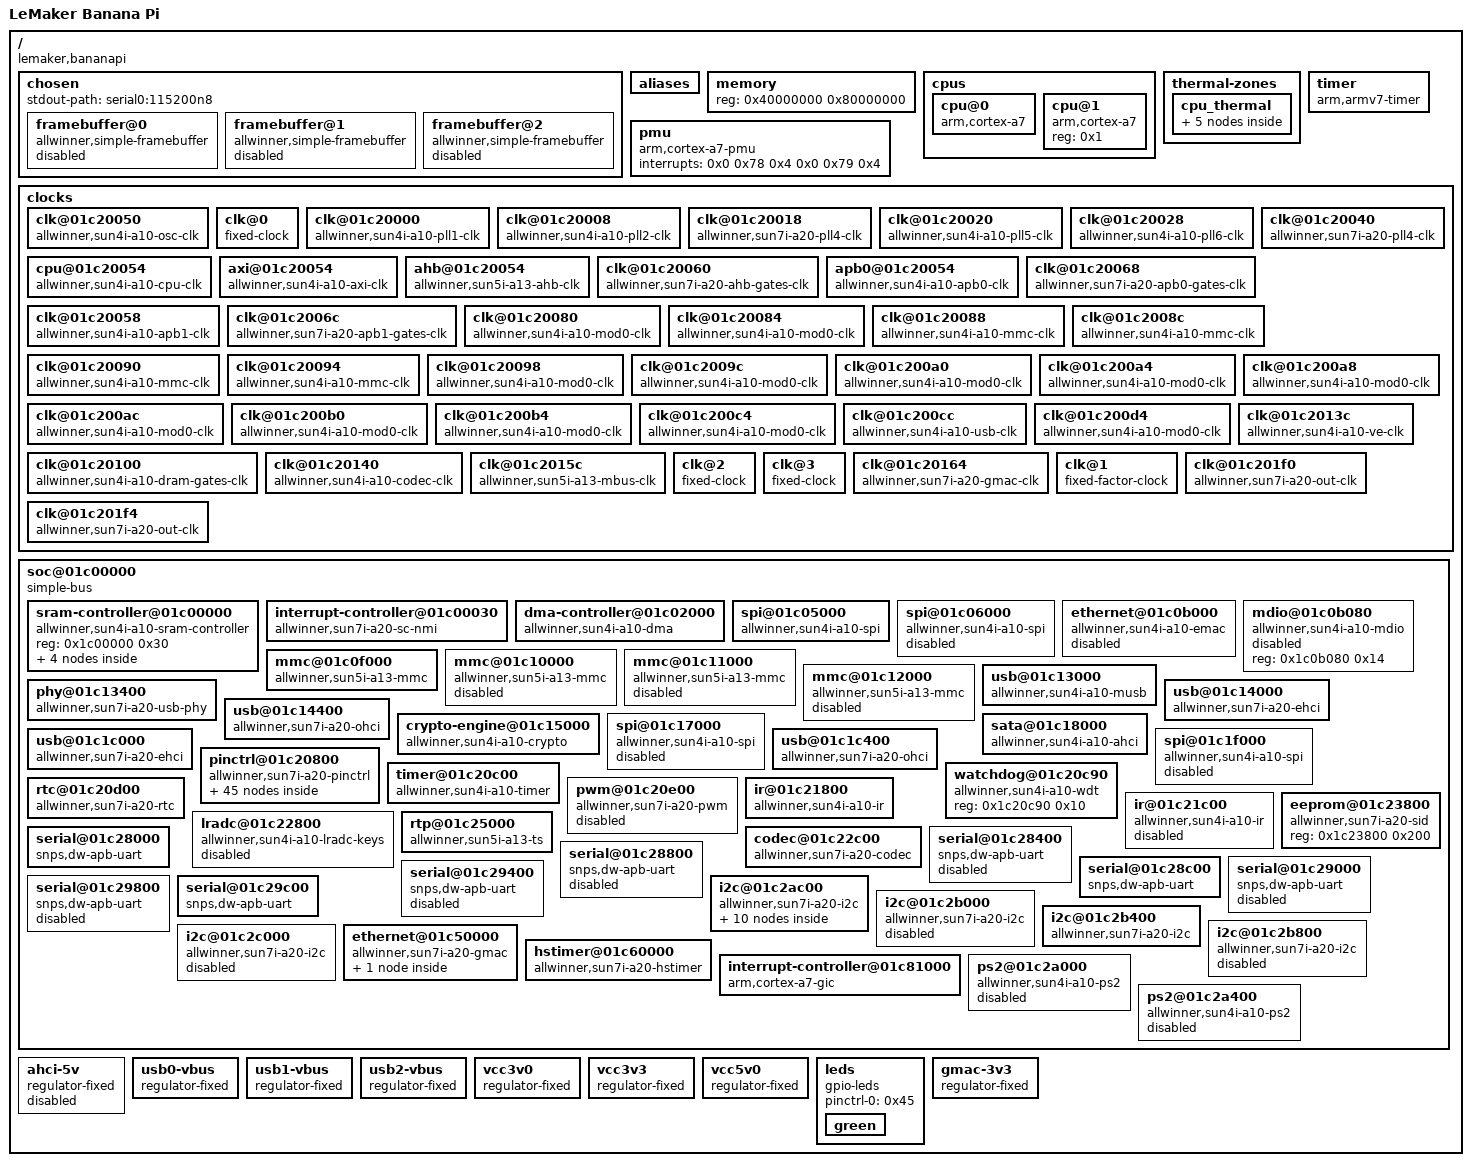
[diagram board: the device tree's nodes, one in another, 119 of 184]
/dts-v1/;

/ {
	#address-cells = <0x1>;
	#size-cells = <0x1>;
	interrupt-parent = <0x1>;
	model = "LeMaker Banana Pi";
	compatible = "lemaker,bananapi", "allwinner,sun7i-a20";

	chosen {
		#address-cells = <0x1>;
		#size-cells = <0x1>;
		ranges;
		stdout-path = "serial0:115200n8";

		framebuffer@0 {
			compatible = "allwinner,simple-framebuffer", "simple-framebuffer";
			allwinner,pipeline = "de_be0-lcd0-hdmi";
			clocks = <0x2 0x1 0x3 0x24 0x3 0x2b 0x3 0x2c 0x4 0x1a>;
			status = "disabled";
		};

		framebuffer@1 {
			compatible = "allwinner,simple-framebuffer", "simple-framebuffer";
			allwinner,pipeline = "de_be0-lcd0";
			clocks = <0x2 0x1 0x3 0x24 0x3 0x2c 0x4 0x1a>;
			status = "disabled";
		};

		framebuffer@2 {
			compatible = "allwinner,simple-framebuffer", "simple-framebuffer";
			allwinner,pipeline = "de_be0-lcd0-tve0";
			clocks = <0x2 0x1 0x3 0x22 0x3 0x24 0x3 0x2c 0x4 0x1a>;
			status = "disabled";
		};
	};

	aliases {
		ethernet0 = "/soc@01c00000/ethernet@01c50000";
		serial0 = "/soc@01c00000/serial@01c28000";
		serial1 = "/soc@01c00000/serial@01c28c00";
		serial2 = "/soc@01c00000/serial@01c29c00";
	};

	memory {
		device_type = "memory";
		reg = <0x40000000 0x80000000>;
	};

	cpus {
		#address-cells = <0x1>;
		#size-cells = <0x0>;

		cpu@0 {
			compatible = "arm,cortex-a7";
			device_type = "cpu";
			reg = <0x0>;
			clocks = <0x5>;
			clock-latency = <0x3b9b0>;
			operating-points = <0xea600 0x155cc0 0xdea80 0x155cc0 0xd2f00 0x149970 0xafc80 0x1312d0 0x80e80 0x118c30 0x4c2c0 0x10c8e0 0x23280 0x100590>;
			#cooling-cells = <0x2>;
			cooling-min-level = <0x0>;
			cooling-max-level = <0x6>;
			cpu-supply = <0x6>;
			linux,phandle = <0x9>;
			phandle = <0x9>;
		};

		cpu@1 {
			compatible = "arm,cortex-a7";
			device_type = "cpu";
			reg = <0x1>;
		};
	};

	thermal-zones {

		cpu_thermal {
			polling-delay-passive = <0xfa>;
			polling-delay = <0x3e8>;
			thermal-sensors = <0x7>;

			cooling-maps {

				map0 {
					trip = <0x8>;
					cooling-device = <0x9 0xffffffff 0xffffffff>;
				};
			};

			trips {

				cpu_alert0 {
					temperature = <0x124f8>;
					hysteresis = <0x7d0>;
					type = "passive";
					linux,phandle = <0x8>;
					phandle = <0x8>;
				};

				cpu_crit {
					temperature = <0x186a0>;
					hysteresis = <0x7d0>;
					type = "critical";
				};
			};
		};
	};

	timer {
		compatible = "arm,armv7-timer";
		interrupts = <0x1 0xd 0xf08 0x1 0xe 0xf08 0x1 0xb 0xf08 0x1 0xa 0xf08>;
	};

	pmu {
		compatible = "arm,cortex-a7-pmu", "arm,cortex-a15-pmu";
		interrupts = <0x0 0x78 0x4 0x0 0x79 0x4>;
	};

	clocks {
		#address-cells = <0x1>;
		#size-cells = <0x1>;
		ranges;

		clk@01c20050 {
			#clock-cells = <0x0>;
			compatible = "allwinner,sun4i-a10-osc-clk";
			reg = <0x1c20050 0x4>;
			clock-frequency = <0x16e3600>;
			clock-output-names = "osc24M";
			linux,phandle = <0xa>;
			phandle = <0xa>;
		};

		clk@0 {
			#clock-cells = <0x0>;
			compatible = "fixed-clock";
			clock-frequency = <0x8000>;
			clock-output-names = "osc32k";
			linux,phandle = <0xb>;
			phandle = <0xb>;
		};

		clk@01c20000 {
			#clock-cells = <0x0>;
			compatible = "allwinner,sun4i-a10-pll1-clk";
			reg = <0x1c20000 0x4>;
			clocks = <0xa>;
			clock-output-names = "pll1";
			linux,phandle = <0xc>;
			phandle = <0xc>;
		};

		clk@01c20008 {
			#clock-cells = <0x1>;
			compatible = "allwinner,sun4i-a10-pll2-clk";
			reg = <0x1c20008 0x8>;
			clocks = <0xa>;
			clock-output-names = "pll2-1x", "pll2-2x", "pll2-4x", "pll2-8x";
			linux,phandle = <0x13>;
			phandle = <0x13>;
		};

		clk@01c20018 {
			#clock-cells = <0x0>;
			compatible = "allwinner,sun7i-a20-pll4-clk";
			reg = <0x1c20018 0x4>;
			clocks = <0xa>;
			clock-output-names = "pll4";
			linux,phandle = <0x12>;
			phandle = <0x12>;
		};

		clk@01c20020 {
			#clock-cells = <0x1>;
			compatible = "allwinner,sun4i-a10-pll5-clk";
			reg = <0x1c20020 0x4>;
			clocks = <0xa>;
			clock-output-names = "pll5_ddr", "pll5_other";
			linux,phandle = <0x2>;
			phandle = <0x2>;
		};

		clk@01c20028 {
			#clock-cells = <0x1>;
			compatible = "allwinner,sun4i-a10-pll6-clk";
			reg = <0x1c20028 0x4>;
			clocks = <0xa>;
			clock-output-names = "pll6_sata", "pll6_other", "pll6", "pll6_div_4";
			linux,phandle = <0xd>;
			phandle = <0xd>;
		};

		clk@01c20040 {
			#clock-cells = <0x0>;
			compatible = "allwinner,sun7i-a20-pll4-clk";
			reg = <0x1c20040 0x4>;
			clocks = <0xa>;
			clock-output-names = "pll8";
		};

		cpu@01c20054 {
			#clock-cells = <0x0>;
			compatible = "allwinner,sun4i-a10-cpu-clk";
			reg = <0x1c20054 0x4>;
			clocks = <0xb 0xa 0xc 0xd 0x1>;
			clock-output-names = "cpu";
			linux,phandle = <0x5>;
			phandle = <0x5>;
		};

		axi@01c20054 {
			#clock-cells = <0x0>;
			compatible = "allwinner,sun4i-a10-axi-clk";
			reg = <0x1c20054 0x4>;
			clocks = <0x5>;
			clock-output-names = "axi";
			linux,phandle = <0xe>;
			phandle = <0xe>;
		};

		ahb@01c20054 {
			#clock-cells = <0x0>;
			compatible = "allwinner,sun5i-a13-ahb-clk";
			reg = <0x1c20054 0x4>;
			clocks = <0xe 0xd 0x3 0xd 0x1>;
			clock-output-names = "ahb";
			assigned-clocks = <0xf>;
			assigned-clock-parents = <0xd 0x3>;
			linux,phandle = <0xf>;
			phandle = <0xf>;
		};

		clk@01c20060 {
			#clock-cells = <0x1>;
			compatible = "allwinner,sun7i-a20-ahb-gates-clk";
			reg = <0x1c20060 0x8>;
			clocks = <0xf>;
			clock-indices = <0x0 0x1 0x2 0x3 0x4 0x5 0x6 0x7 0x8 0x9 0xa 0xb 0xc 0xd 0xe 0x10 0x11 0x12 0x14 0x15 0x16 0x17 0x19 0x1c 0x20 0x21 0x22 0x23 0x24 0x25 0x28 0x29 0x2a 0x2b 0x2c 0x2d 0x2e 0x2f 0x31 0x32 0x34>;
			clock-output-names = "ahb_usb0", "ahb_ehci0", "ahb_ohci0", "ahb_ehci1", "ahb_ohci1", "ahb_ss", "ahb_dma", "ahb_bist", "ahb_mmc0", "ahb_mmc1", "ahb_mmc2", "ahb_mmc3", "ahb_ms", "ahb_nand", "ahb_sdram", "ahb_ace", "ahb_emac", "ahb_ts", "ahb_spi0", "ahb_spi1", "ahb_spi2", "ahb_spi3", "ahb_sata", "ahb_hstimer", "ahb_ve", "ahb_tvd", "ahb_tve0", "ahb_tve1", "ahb_lcd0", "ahb_lcd1", "ahb_csi0", "ahb_csi1", "ahb_hdmi1", "ahb_hdmi0", "ahb_de_be0", "ahb_de_be1", "ahb_de_fe0", "ahb_de_fe1", "ahb_gmac", "ahb_mp", "ahb_mali";
			linux,phandle = <0x3>;
			phandle = <0x3>;
		};

		apb0@01c20054 {
			#clock-cells = <0x0>;
			compatible = "allwinner,sun4i-a10-apb0-clk";
			reg = <0x1c20054 0x4>;
			clocks = <0xf>;
			clock-output-names = "apb0";
			linux,phandle = <0x10>;
			phandle = <0x10>;
		};

		clk@01c20068 {
			#clock-cells = <0x1>;
			compatible = "allwinner,sun7i-a20-apb0-gates-clk";
			reg = <0x1c20068 0x4>;
			clocks = <0x10>;
			clock-indices = <0x0 0x1 0x2 0x3 0x4 0x5 0x6 0x7 0x8 0xa>;
			clock-output-names = "apb0_codec", "apb0_spdif", "apb0_ac97", "apb0_iis0", "apb0_iis1", "apb0_pio", "apb0_ir0", "apb0_ir1", "apb0_iis2", "apb0_keypad";
			linux,phandle = <0x31>;
			phandle = <0x31>;
		};

		clk@01c20058 {
			#clock-cells = <0x0>;
			compatible = "allwinner,sun4i-a10-apb1-clk";
			reg = <0x1c20058 0x4>;
			clocks = <0xa 0xd 0x1 0xb>;
			clock-output-names = "apb1";
			linux,phandle = <0x11>;
			phandle = <0x11>;
		};

		clk@01c2006c {
			#clock-cells = <0x1>;
			compatible = "allwinner,sun7i-a20-apb1-gates-clk";
			reg = <0x1c2006c 0x4>;
			clocks = <0x11>;
			clock-indices = <0x0 0x1 0x2 0x3 0x4 0x5 0x6 0x7 0xf 0x10 0x11 0x12 0x13 0x14 0x15 0x16 0x17>;
			clock-output-names = "apb1_i2c0", "apb1_i2c1", "apb1_i2c2", "apb1_i2c3", "apb1_can", "apb1_scr", "apb1_ps20", "apb1_ps21", "apb1_i2c4", "apb1_uart0", "apb1_uart1", "apb1_uart2", "apb1_uart3", "apb1_uart4", "apb1_uart5", "apb1_uart6", "apb1_uart7";
			linux,phandle = <0x36>;
			phandle = <0x36>;
		};

		clk@01c20080 {
			#clock-cells = <0x0>;
			compatible = "allwinner,sun4i-a10-mod0-clk";
			reg = <0x1c20080 0x4>;
			clocks = <0xa 0xd 0x1 0x2 0x1>;
			clock-output-names = "nand";
		};

		clk@01c20084 {
			#clock-cells = <0x0>;
			compatible = "allwinner,sun4i-a10-mod0-clk";
			reg = <0x1c20084 0x4>;
			clocks = <0xa 0xd 0x1 0x2 0x1>;
			clock-output-names = "ms";
		};

		clk@01c20088 {
			#clock-cells = <0x1>;
			compatible = "allwinner,sun4i-a10-mmc-clk";
			reg = <0x1c20088 0x4>;
			clocks = <0xa 0xd 0x1 0x2 0x1>;
			clock-output-names = "mmc0", "mmc0_output", "mmc0_sample";
			linux,phandle = <0x1e>;
			phandle = <0x1e>;
		};

		clk@01c2008c {
			#clock-cells = <0x1>;
			compatible = "allwinner,sun4i-a10-mmc-clk";
			reg = <0x1c2008c 0x4>;
			clocks = <0xa 0xd 0x1 0x2 0x1>;
			clock-output-names = "mmc1", "mmc1_output", "mmc1_sample";
			linux,phandle = <0x23>;
			phandle = <0x23>;
		};

		clk@01c20090 {
			#clock-cells = <0x1>;
			compatible = "allwinner,sun4i-a10-mmc-clk";
			reg = <0x1c20090 0x4>;
			clocks = <0xa 0xd 0x1 0x2 0x1>;
			clock-output-names = "mmc2", "mmc2_output", "mmc2_sample";
			linux,phandle = <0x24>;
			phandle = <0x24>;
		};

		clk@01c20094 {
			#clock-cells = <0x1>;
			compatible = "allwinner,sun4i-a10-mmc-clk";
			reg = <0x1c20094 0x4>;
			clocks = <0xa 0xd 0x1 0x2 0x1>;
			clock-output-names = "mmc3", "mmc3_output", "mmc3_sample";
			linux,phandle = <0x25>;
			phandle = <0x25>;
		};

		clk@01c20098 {
			#clock-cells = <0x0>;
			compatible = "allwinner,sun4i-a10-mod0-clk";
			reg = <0x1c20098 0x4>;
			clocks = <0xa 0xd 0x1 0x2 0x1>;
			clock-output-names = "ts";
		};

		clk@01c2009c {
			#clock-cells = <0x0>;
			compatible = "allwinner,sun4i-a10-mod0-clk";
			reg = <0x1c2009c 0x4>;
			clocks = <0xa 0xd 0x1 0x2 0x1>;
			clock-output-names = "ss";
			linux,phandle = <0x2e>;
			phandle = <0x2e>;
		};

		clk@01c200a0 {
			#clock-cells = <0x0>;
			compatible = "allwinner,sun4i-a10-mod0-clk";
			reg = <0x1c200a0 0x4>;
			clocks = <0xa 0xd 0x1 0x2 0x1>;
			clock-output-names = "spi0";
			linux,phandle = <0x17>;
			phandle = <0x17>;
		};

		clk@01c200a4 {
			#clock-cells = <0x0>;
			compatible = "allwinner,sun4i-a10-mod0-clk";
			reg = <0x1c200a4 0x4>;
			clocks = <0xa 0xd 0x1 0x2 0x1>;
			clock-output-names = "spi1";
			linux,phandle = <0x1c>;
			phandle = <0x1c>;
		};

		clk@01c200a8 {
			#clock-cells = <0x0>;
			compatible = "allwinner,sun4i-a10-mod0-clk";
			reg = <0x1c200a8 0x4>;
			clocks = <0xa 0xd 0x1 0x2 0x1>;
			clock-output-names = "spi2";
			linux,phandle = <0x2f>;
			phandle = <0x2f>;
		};

		clk@01c200ac {
			#clock-cells = <0x0>;
			compatible = "allwinner,sun4i-a10-mod0-clk";
			reg = <0x1c200ac 0x4>;
			clocks = <0xa 0xd 0x1 0x2 0x1>;
			clock-output-names = "pata";
		};

		clk@01c200b0 {
			#clock-cells = <0x0>;
			compatible = "allwinner,sun4i-a10-mod0-clk";
			reg = <0x1c200b0 0x4>;
			clocks = <0xa 0xd 0x1 0x2 0x1>;
			clock-output-names = "ir0";
			linux,phandle = <0x32>;
			phandle = <0x32>;
		};

		clk@01c200b4 {
			#clock-cells = <0x0>;
			compatible = "allwinner,sun4i-a10-mod0-clk";
			reg = <0x1c200b4 0x4>;
			clocks = <0xa 0xd 0x1 0x2 0x1>;
			clock-output-names = "ir1";
			linux,phandle = <0x34>;
			phandle = <0x34>;
		};

		clk@01c200c4 {
			#clock-cells = <0x0>;
			compatible = "allwinner,sun4i-a10-mod0-clk";
			reg = <0x1c200c4 0x4>;
			clocks = <0xa>;
			clock-output-names = "keypad";
		};

		clk@01c200cc {
			#clock-cells = <0x1>;
			#reset-cells = <0x1>;
			compatible = "allwinner,sun4i-a10-usb-clk";
			reg = <0x1c200cc 0x4>;
			clocks = <0xd 0x1>;
			clock-output-names = "usb_ohci0", "usb_ohci1", "usb_phy";
			linux,phandle = <0x28>;
			phandle = <0x28>;
		};

		clk@01c200d4 {
			#clock-cells = <0x0>;
			compatible = "allwinner,sun4i-a10-mod0-clk";
			reg = <0x1c200d4 0x4>;
			clocks = <0xa 0xd 0x1 0x2 0x1>;
			clock-output-names = "spi3";
			linux,phandle = <0x30>;
			phandle = <0x30>;
		};

		clk@01c20100 {
			#clock-cells = <0x1>;
			compatible = "allwinner,sun4i-a10-dram-gates-clk";
			reg = <0x1c20100 0x4>;
			clocks = <0x2 0x0>;
			clock-indices = <0x0 0x1 0x2 0x3 0x4 0x5 0x6 0xf 0x18 0x19 0x1a 0x1b 0x1c 0x1d>;
			clock-output-names = "dram_ve", "dram_csi0", "dram_csi1", "dram_ts", "dram_tvd", "dram_tve0", "dram_tve1", "dram_output", "dram_de_fe1", "dram_de_fe0", "dram_de_be0", "dram_de_be1", "dram_de_mp", "dram_ace";
			linux,phandle = <0x4>;
			phandle = <0x4>;
		};

		clk@01c2013c {
			#clock-cells = <0x0>;
			#reset-cells = <0x0>;
			compatible = "allwinner,sun4i-a10-ve-clk";
			reg = <0x1c2013c 0x4>;
			clocks = <0x12>;
			clock-output-names = "ve";
		};

		clk@01c20140 {
			#clock-cells = <0x0>;
			compatible = "allwinner,sun4i-a10-codec-clk";
			reg = <0x1c20140 0x4>;
			clocks = <0x13 0x0>;
			clock-output-names = "codec";
			linux,phandle = <0x35>;
			phandle = <0x35>;
		};

		clk@01c2015c {
			#clock-cells = <0x0>;
			compatible = "allwinner,sun5i-a13-mbus-clk";
			reg = <0x1c2015c 0x4>;
			clocks = <0xa 0xd 0x2 0x2 0x1>;
			clock-output-names = "mbus";
		};

		clk@2 {
			#clock-cells = <0x0>;
			compatible = "fixed-clock";
			clock-frequency = <0x17d7840>;
			clock-output-names = "mii_phy_tx";
			linux,phandle = <0x14>;
			phandle = <0x14>;
		};

		clk@3 {
			#clock-cells = <0x0>;
			compatible = "fixed-clock";
			clock-frequency = <0x7735940>;
			clock-output-names = "gmac_int_tx";
			linux,phandle = <0x15>;
			phandle = <0x15>;
		};

		clk@01c20164 {
			#clock-cells = <0x0>;
			compatible = "allwinner,sun7i-a20-gmac-clk";
			reg = <0x1c20164 0x4>;
			clocks = <0x14 0x15>;
			clock-output-names = "gmac_tx";
			linux,phandle = <0x3d>;
			phandle = <0x3d>;
		};

		clk@1 {
			#clock-cells = <0x0>;
			compatible = "fixed-factor-clock";
			clock-div = <0x2ee>;
			clock-mult = <0x1>;
			clocks = <0xa>;
			clock-output-names = "osc24M_32k";
			linux,phandle = <0x16>;
			phandle = <0x16>;
		};

		clk@01c201f0 {
			#clock-cells = <0x0>;
			compatible = "allwinner,sun7i-a20-out-clk";
			reg = <0x1c201f0 0x4>;
			clocks = <0x16 0xb 0xa>;
			clock-output-names = "clk_out_a";
		};

		clk@01c201f4 {
			#clock-cells = <0x0>;
			compatible = "allwinner,sun7i-a20-out-clk";
			reg = <0x1c201f4 0x4>;
			clocks = <0x16 0xb 0xa>;
			clock-output-names = "clk_out_b";
		};
	};

	soc@01c00000 {
		compatible = "simple-bus";
		#address-cells = <0x1>;
		#size-cells = <0x1>;
		ranges;

		sram-controller@01c00000 {
			compatible = "allwinner,sun4i-a10-sram-controller";
			reg = <0x1c00000 0x30>;
			#address-cells = <0x1>;
			#size-cells = <0x1>;
			ranges;

			sram@00000000 {
				compatible = "mmio-sram";
				reg = <0x0 0xc000>;
				#address-cells = <0x1>;
				#size-cells = <0x1>;
				ranges = <0x0 0x0 0xc000>;

				sram-section@8000 {
					compatible = "allwinner,sun4i-a10-sram-a3-a4";
					reg = <0x8000 0x4000>;
					status = "disabled";
					linux,phandle = <0x1d>;
					phandle = <0x1d>;
				};
			};

			sram@00010000 {
				compatible = "mmio-sram";
				reg = <0x10000 0x1000>;
				#address-cells = <0x1>;
				#size-cells = <0x1>;
				ranges = <0x0 0x10000 0x1000>;

				sram-section@0000 {
					compatible = "allwinner,sun4i-a10-sram-d";
					reg = <0x0 0x1000>;
					status = "okay";
					linux,phandle = <0x27>;
					phandle = <0x27>;
				};
			};
		};

		interrupt-controller@01c00030 {
			compatible = "allwinner,sun7i-a20-sc-nmi";
			interrupt-controller;
			#interrupt-cells = <0x2>;
			reg = <0x1c00030 0xc>;
			interrupts = <0x0 0x0 0x4>;
			linux,phandle = <0x3b>;
			phandle = <0x3b>;
		};

		dma-controller@01c02000 {
			compatible = "allwinner,sun4i-a10-dma";
			reg = <0x1c02000 0x1000>;
			interrupts = <0x0 0x1b 0x4>;
			clocks = <0x3 0x6>;
			#dma-cells = <0x2>;
			linux,phandle = <0x18>;
			phandle = <0x18>;
		};

		spi@01c05000 {
			compatible = "allwinner,sun4i-a10-spi";
			reg = <0x1c05000 0x1000>;
			interrupts = <0x0 0xa 0x4>;
			clocks = <0x3 0x14 0x17>;
			clock-names = "ahb", "mod";
			dmas = <0x18 0x1 0x1b 0x18 0x1 0x1a>;
			dma-names = "rx", "tx";
			status = "okay";
			#address-cells = <0x1>;
			#size-cells = <0x0>;
			pinctrl-names = "default";
			pinctrl-0 = <0x19 0x1a 0x1b>;
		};

		spi@01c06000 {
			compatible = "allwinner,sun4i-a10-spi";
			reg = <0x1c06000 0x1000>;
			interrupts = <0x0 0xb 0x4>;
			clocks = <0x3 0x15 0x1c>;
			clock-names = "ahb", "mod";
			dmas = <0x18 0x1 0x9 0x18 0x1 0x8>;
			dma-names = "rx", "tx";
			status = "disabled";
			#address-cells = <0x1>;
			#size-cells = <0x0>;
		};

		ethernet@01c0b000 {
			compatible = "allwinner,sun4i-a10-emac";
			reg = <0x1c0b000 0x1000>;
			interrupts = <0x0 0x37 0x4>;
			clocks = <0x3 0x11>;
			allwinner,sram = <0x1d 0x1>;
			status = "disabled";
		};

		mdio@01c0b080 {
			compatible = "allwinner,sun4i-a10-mdio";
			reg = <0x1c0b080 0x14>;
			status = "disabled";
			#address-cells = <0x1>;
			#size-cells = <0x0>;
		};

		mmc@01c0f000 {
			compatible = "allwinner,sun5i-a13-mmc";
			reg = <0x1c0f000 0x1000>;
			clocks = <0x3 0x8 0x1e 0x0 0x1e 0x1 0x1e 0x2>;
			clock-names = "ahb", "mmc", "output", "sample";
			interrupts = <0x0 0x20 0x4>;
			status = "okay";
			#address-cells = <0x1>;
			#size-cells = <0x0>;
			pinctrl-names = "default";
			pinctrl-0 = <0x1f 0x20>;
			vmmc-supply = <0x21>;
			bus-width = <0x4>;
			cd-gpios = <0x22 0x7 0xa 0x0>;
			cd-inverted;
		};

		mmc@01c10000 {
			compatible = "allwinner,sun5i-a13-mmc";
			reg = <0x1c10000 0x1000>;
			clocks = <0x3 0x9 0x23 0x0 0x23 0x1 0x23 0x2>;
			clock-names = "ahb", "mmc", "output", "sample";
			interrupts = <0x0 0x21 0x4>;
			status = "disabled";
			#address-cells = <0x1>;
			#size-cells = <0x0>;
		};

		mmc@01c11000 {
			compatible = "allwinner,sun5i-a13-mmc";
			reg = <0x1c11000 0x1000>;
			clocks = <0x3 0xa 0x24 0x0 0x24 0x1 0x24 0x2>;
			clock-names = "ahb", "mmc", "output", "sample";
			interrupts = <0x0 0x22 0x4>;
			status = "disabled";
			#address-cells = <0x1>;
			#size-cells = <0x0>;
		};

		mmc@01c12000 {
			compatible = "allwinner,sun5i-a13-mmc";
			reg = <0x1c12000 0x1000>;
			clocks = <0x3 0xb 0x25 0x0 0x25 0x1 0x25 0x2>;
			clock-names = "ahb", "mmc", "output", "sample";
			interrupts = <0x0 0x23 0x4>;
			status = "disabled";
			#address-cells = <0x1>;
			#size-cells = <0x0>;
		};

		usb@01c13000 {
			compatible = "allwinner,sun4i-a10-musb";
			reg = <0x1c13000 0x400>;
			clocks = <0x3 0x0>;
			interrupts = <0x0 0x26 0x4>;
			interrupt-names = "mc";
			phys = <0x26 0x0>;
			phy-names = "usb";
			extcon = <0x26 0x0>;
			allwinner,sram = <0x27 0x1>;
			status = "okay";
			dr_mode = "otg";
		};

		phy@01c13400 {
			#phy-cells = <0x1>;
			compatible = "allwinner,sun7i-a20-usb-phy";
			reg = <0x1c13400 0x10 0x1c14800 0x4 0x1c1c800 0x4>;
			reg-names = "phy_ctrl", "pmu1", "pmu2";
			clocks = <0x28 0x8>;
			clock-names = "usb_phy";
			resets = <0x28 0x0 0x28 0x1 0x28 0x2>;
			reset-names = "usb0_reset", "usb1_reset", "usb2_reset";
			status = "okay";
			pinctrl-names = "default";
			pinctrl-0 = <0x29>;
			usb0_vbus-supply = <0x2b>;
			usb1_vbus-supply = <0x2c>;
			usb2_vbus-supply = <0x2d>;
			linux,phandle = <0x26>;
			phandle = <0x26>;
		};

		usb@01c14000 {
			compatible = "allwinner,sun7i-a20-ehci", "generic-ehci";
			reg = <0x1c14000 0x100>;
			interrupts = <0x0 0x27 0x4>;
			clocks = <0x3 0x1>;
			phys = <0x26 0x1>;
			phy-names = "usb";
			status = "okay";
		};

		usb@01c14400 {
			compatible = "allwinner,sun7i-a20-ohci", "generic-ohci";
			reg = <0x1c14400 0x100>;
			interrupts = <0x0 0x40 0x4>;
			clocks = <0x28 0x6 0x3 0x2>;
			phys = <0x26 0x1>;
			phy-names = "usb";
			status = "okay";
		};

		crypto-engine@01c15000 {
			compatible = "allwinner,sun4i-a10-crypto";
			reg = <0x1c15000 0x1000>;
			interrupts = <0x0 0x56 0x4>;
			clocks = <0x3 0x5 0x2e>;
			clock-names = "ahb", "mod";
		};

		spi@01c17000 {
			compatible = "allwinner,sun4i-a10-spi";
			reg = <0x1c17000 0x1000>;
			interrupts = <0x0 0xc 0x4>;
			clocks = <0x3 0x16 0x2f>;
			clock-names = "ahb", "mod";
			dmas = <0x18 0x1 0x1d 0x18 0x1 0x1c>;
			dma-names = "rx", "tx";
			status = "disabled";
			#address-cells = <0x1>;
			#size-cells = <0x0>;
		};

		sata@01c18000 {
			compatible = "allwinner,sun4i-a10-ahci";
			reg = <0x1c18000 0x1000>;
			interrupts = <0x0 0x38 0x4>;
			clocks = <0xd 0x0 0x3 0x19>;
			status = "okay";
		};

		usb@01c1c000 {
			compatible = "allwinner,sun7i-a20-ehci", "generic-ehci";
			reg = <0x1c1c000 0x100>;
			interrupts = <0x0 0x28 0x4>;
			clocks = <0x3 0x3>;
			phys = <0x26 0x2>;
			phy-names = "usb";
			status = "okay";
		};

		usb@01c1c400 {
			compatible = "allwinner,sun7i-a20-ohci", "generic-ohci";
			reg = <0x1c1c400 0x100>;
			interrupts = <0x0 0x41 0x4>;
			clocks = <0x28 0x7 0x3 0x4>;
			phys = <0x26 0x2>;
			phy-names = "usb";
			status = "okay";
		};

		spi@01c1f000 {
			compatible = "allwinner,sun4i-a10-spi";
			reg = <0x1c1f000 0x1000>;
			interrupts = <0x0 0x32 0x4>;
			clocks = <0x3 0x17 0x30>;
			clock-names = "ahb", "mod";
			dmas = <0x18 0x1 0x1f 0x18 0x1 0x1e>;
			dma-names = "rx", "tx";
			status = "disabled";
			#address-cells = <0x1>;
			#size-cells = <0x0>;
		};

		pinctrl@01c20800 {
			compatible = "allwinner,sun7i-a20-pinctrl";
			reg = <0x1c20800 0x400>;
			interrupts = <0x0 0x1c 0x4>;
			clocks = <0x31 0x5>;
			gpio-controller;
			interrupt-controller;
			#interrupt-cells = <0x3>;
			#gpio-cells = <0x3>;
			linux,phandle = <0x22>;
			phandle = <0x22>;

			pwm0@0 {
				allwinner,pins = "PB2";
				allwinner,function = "pwm";
				allwinner,drive = <0x0>;
				allwinner,pull = <0x0>;
			};

			pwm1@0 {
				allwinner,pins = "PI3";
				allwinner,function = "pwm";
				allwinner,drive = <0x0>;
				allwinner,pull = <0x0>;
			};

			uart0@0 {
				allwinner,pins = "PB22", "PB23";
				allwinner,function = "uart0";
				allwinner,drive = <0x0>;
				allwinner,pull = <0x0>;
				linux,phandle = <0x37>;
				phandle = <0x37>;
			};

			uart2@0 {
				allwinner,pins = "PI16", "PI17", "PI18", "PI19";
				allwinner,function = "uart2";
				allwinner,drive = <0x0>;
				allwinner,pull = <0x0>;
			};

			uart3@0 {
				allwinner,pins = "PG6", "PG7", "PG8", "PG9";
				allwinner,function = "uart3";
				allwinner,drive = <0x0>;
				allwinner,pull = <0x0>;
			};

			uart3@1 {
				allwinner,pins = "PH0", "PH1";
				allwinner,function = "uart3";
				allwinner,drive = <0x0>;
				allwinner,pull = <0x0>;
				linux,phandle = <0x38>;
				phandle = <0x38>;
			};

			uart4@0 {
				allwinner,pins = "PG10", "PG11";
				allwinner,function = "uart4";
				allwinner,drive = <0x0>;
				allwinner,pull = <0x0>;
			};

			uart4@1 {
				allwinner,pins = "PH4", "PH5";
				allwinner,function = "uart4";
				allwinner,drive = <0x0>;
				allwinner,pull = <0x0>;
			};

			uart5@0 {
				allwinner,pins = "PI10", "PI11";
				allwinner,function = "uart5";
				allwinner,drive = <0x0>;
				allwinner,pull = <0x0>;
			};

			uart6@0 {
				allwinner,pins = "PI12", "PI13";
				allwinner,function = "uart6";
				allwinner,drive = <0x0>;
				allwinner,pull = <0x0>;
			};

			uart7@0 {
				allwinner,pins = "PI20", "PI21";
				allwinner,function = "uart7";
				allwinner,drive = <0x0>;
				allwinner,pull = <0x0>;
				linux,phandle = <0x39>;
				phandle = <0x39>;
			};

			i2c0@0 {
				allwinner,pins = "PB0", "PB1";
				allwinner,function = "i2c0";
				allwinner,drive = <0x0>;
				allwinner,pull = <0x0>;
				linux,phandle = <0x3a>;
				phandle = <0x3a>;
			};

			i2c1@0 {
				allwinner,pins = "PB18", "PB19";
				allwinner,function = "i2c1";
				allwinner,drive = <0x0>;
				allwinner,pull = <0x0>;
			};

			i2c2@0 {
				allwinner,pins = "PB20", "PB21";
				allwinner,function = "i2c2";
				allwinner,drive = <0x0>;
				allwinner,pull = <0x0>;
				linux,phandle = <0x3c>;
				phandle = <0x3c>;
			};

			i2c3@0 {
				allwinner,pins = "PI0", "PI1";
				allwinner,function = "i2c3";
				allwinner,drive = <0x0>;
				allwinner,pull = <0x0>;
			};

			emac0@0 {
				allwinner,pins = "PA0", "PA1", "PA2", "PA3", "PA4", "PA5", "PA6", "PA7", "PA8", "PA9", "PA10", "PA11", "PA12", "PA13", "PA14", "PA15", "PA16";
				allwinner,function = "emac";
				allwinner,drive = <0x0>;
				allwinner,pull = <0x0>;
			};

			clk_out_a@0 {
				allwinner,pins = "PI12";
				allwinner,function = "clk_out_a";
				allwinner,drive = <0x0>;
				allwinner,pull = <0x0>;
			};

			clk_out_b@0 {
				allwinner,pins = "PI13";
				allwinner,function = "clk_out_b";
				allwinner,drive = <0x0>;
				allwinner,pull = <0x0>;
			};

			gmac_mii@0 {
				allwinner,pins = "PA0", "PA1", "PA2", "PA3", "PA4", "PA5", "PA6", "PA7", "PA8", "PA9", "PA10", "PA11", "PA12", "PA13", "PA14", "PA15", "PA16";
				allwinner,function = "gmac";
				allwinner,drive = <0x0>;
				allwinner,pull = <0x0>;
			};

			gmac_rgmii@0 {
				allwinner,pins = "PA0", "PA1", "PA2", "PA3", "PA4", "PA5", "PA6", "PA7", "PA8", "PA10", "PA11", "PA12", "PA13", "PA15", "PA16";
				allwinner,function = "gmac";
				allwinner,drive = <0x3>;
				allwinner,pull = <0x0>;
				linux,phandle = <0x3e>;
				phandle = <0x3e>;
			};

			spi0@0 {
				allwinner,pins = "PI11", "PI12", "PI13";
				allwinner,function = "spi0";
				allwinner,drive = <0x0>;
				allwinner,pull = <0x0>;
				linux,phandle = <0x19>;
				phandle = <0x19>;
			};

			spi0_cs0@0 {
				allwinner,pins = "PI10";
				allwinner,function = "spi0";
				allwinner,drive = <0x0>;
				allwinner,pull = <0x0>;
				linux,phandle = <0x1a>;
				phandle = <0x1a>;
			};

			spi0_cs1@0 {
				allwinner,pins = "PI14";
				allwinner,function = "spi0";
				allwinner,drive = <0x0>;
				allwinner,pull = <0x0>;
				linux,phandle = <0x1b>;
				phandle = <0x1b>;
			};

			spi1@0 {
				allwinner,pins = "PI17", "PI18", "PI19";
				allwinner,function = "spi1";
				allwinner,drive = <0x0>;
				allwinner,pull = <0x0>;
			};

			spi1_cs0@0 {
				allwinner,pins = "PI16";
				allwinner,function = "spi1";
				allwinner,drive = <0x0>;
				allwinner,pull = <0x0>;
			};

			spi2@0 {
				allwinner,pins = "PC20", "PC21", "PC22";
				allwinner,function = "spi2";
				allwinner,drive = <0x0>;
				allwinner,pull = <0x0>;
			};

			spi2@1 {
				allwinner,pins = "PB15", "PB16", "PB17";
				allwinner,function = "spi2";
				allwinner,drive = <0x0>;
				allwinner,pull = <0x0>;
			};

			spi2_cs0@0 {
				allwinner,pins = "PC19";
				allwinner,function = "spi2";
				allwinner,drive = <0x0>;
				allwinner,pull = <0x0>;
			};

			spi2_cs0@1 {
				allwinner,pins = "PB14";
				allwinner,function = "spi2";
				allwinner,drive = <0x0>;
				allwinner,pull = <0x0>;
			};

			mmc0@0 {
				allwinner,pins = "PF0", "PF1", "PF2", "PF3", "PF4", "PF5";
				allwinner,function = "mmc0";
				allwinner,drive = <0x2>;
				allwinner,pull = <0x0>;
				linux,phandle = <0x1f>;
				phandle = <0x1f>;
			};

			mmc0_cd_pin@0 {
				allwinner,pins = "PH10";
				allwinner,function = "gpio_in";
				allwinner,drive = <0x0>;
				allwinner,pull = <0x1>;
				linux,phandle = <0x20>;
				phandle = <0x20>;
			};

			mmc2@0 {
				allwinner,pins = "PC6", "PC7", "PC8", "PC9", "PC10", "PC11";
				allwinner,function = "mmc2";
				allwinner,drive = <0x2>;
				allwinner,pull = <0x1>;
			};

			mmc3@0 {
				allwinner,pins = "PI4", "PI5", "PI6", "PI7", "PI8", "PI9";
				allwinner,function = "mmc3";
				allwinner,drive = <0x2>;
				allwinner,pull = <0x0>;
			};

			ir0@0 {
				allwinner,pins = "PB4";
				allwinner,function = "ir0";
				allwinner,drive = <0x0>;
				allwinner,pull = <0x0>;
				linux,phandle = <0x33>;
				phandle = <0x33>;
			};

			ir0@1 {
				allwinner,pins = "PB3";
				allwinner,function = "ir0";
				allwinner,drive = <0x0>;
				allwinner,pull = <0x0>;
			};

			ir1@0 {
				allwinner,pins = "PB23";
				allwinner,function = "ir1";
				allwinner,drive = <0x0>;
				allwinner,pull = <0x0>;
			};

			ir1@1 {
				allwinner,pins = "PB22";
				allwinner,function = "ir1";
				allwinner,drive = <0x0>;
				allwinner,pull = <0x0>;
			};

			ps20@0 {
				allwinner,pins = "PI20", "PI21";
				allwinner,function = "ps2";
				allwinner,drive = <0x0>;
				allwinner,pull = <0x0>;
			};

			ps21@0 {
				allwinner,pins = "PH12", "PH13";
				allwinner,function = "ps2";
				allwinner,drive = <0x0>;
				allwinner,pull = <0x0>;
			};

			ahci_pwr_pin@0 {
				allwinner,pins = "PB8";
				allwinner,function = "gpio_out";
				allwinner,drive = <0x0>;
				allwinner,pull = <0x0>;
				linux,phandle = <0x41>;
				phandle = <0x41>;
			};

			usb0_vbus_pin@0 {
				allwinner,pins = "PB9";
				allwinner,function = "gpio_out";
				allwinner,drive = <0x0>;
				allwinner,pull = <0x0>;
				linux,phandle = <0x42>;
				phandle = <0x42>;
			};

			usb1_vbus_pin@0 {
				allwinner,pins = "PH6";
				allwinner,function = "gpio_out";
				allwinner,drive = <0x0>;
				allwinner,pull = <0x0>;
				linux,phandle = <0x43>;
				phandle = <0x43>;
			};

			usb2_vbus_pin@0 {
				allwinner,pins = "PH3";
				allwinner,function = "gpio_out";
				allwinner,drive = <0x0>;
				allwinner,pull = <0x0>;
				linux,phandle = <0x44>;
				phandle = <0x44>;
			};

			gmac_power_pin@0 {
				allwinner,pins = "PH23";
				allwinner,function = "gpio_out";
				allwinner,drive = <0x0>;
				allwinner,pull = <0x0>;
				linux,phandle = <0x46>;
				phandle = <0x46>;
			};

			led_pins@0 {
				allwinner,pins = "PH24";
				allwinner,function = "gpio_out";
				allwinner,drive = <0x0>;
				allwinner,pull = <0x0>;
				linux,phandle = <0x45>;
				phandle = <0x45>;
			};
		};

		timer@01c20c00 {
			compatible = "allwinner,sun4i-a10-timer";
			reg = <0x1c20c00 0x90>;
			interrupts = <0x0 0x16 0x4 0x0 0x17 0x4 0x0 0x18 0x4 0x0 0x19 0x4 0x0 0x43 0x4 0x0 0x44 0x4>;
			clocks = <0xa>;
		};

		watchdog@01c20c90 {
			compatible = "allwinner,sun4i-a10-wdt";
			reg = <0x1c20c90 0x10>;
		};

		rtc@01c20d00 {
			compatible = "allwinner,sun7i-a20-rtc";
			reg = <0x1c20d00 0x20>;
			interrupts = <0x0 0x18 0x4>;
		};

		pwm@01c20e00 {
			compatible = "allwinner,sun7i-a20-pwm";
			reg = <0x1c20e00 0xc>;
			clocks = <0xa>;
			#pwm-cells = <0x3>;
			status = "disabled";
		};

		ir@01c21800 {
			compatible = "allwinner,sun4i-a10-ir";
			clocks = <0x31 0x6 0x32>;
			clock-names = "apb", "ir";
			interrupts = <0x0 0x5 0x4>;
			reg = <0x1c21800 0x40>;
			status = "okay";
			pinctrl-names = "default";
			pinctrl-0 = <0x33>;
		};

		ir@01c21c00 {
			compatible = "allwinner,sun4i-a10-ir";
			clocks = <0x31 0x7 0x34>;
			clock-names = "apb", "ir";
			interrupts = <0x0 0x6 0x4>;
			reg = <0x1c21c00 0x40>;
			status = "disabled";
		};

		lradc@01c22800 {
			compatible = "allwinner,sun4i-a10-lradc-keys";
			reg = <0x1c22800 0x100>;
			interrupts = <0x0 0x1f 0x4>;
			status = "disabled";
		};

		codec@01c22c00 {
			#sound-dai-cells = <0x0>;
			compatible = "allwinner,sun7i-a20-codec";
			reg = <0x1c22c00 0x40>;
			interrupts = <0x0 0x1e 0x4>;
			clocks = <0x31 0x0 0x35>;
			clock-names = "apb", "codec";
			dmas = <0x18 0x0 0x13 0x18 0x0 0x13>;
			dma-names = "rx", "tx";
			status = "okay";
		};

		eeprom@01c23800 {
			compatible = "allwinner,sun7i-a20-sid";
			reg = <0x1c23800 0x200>;
		};

		rtp@01c25000 {
			compatible = "allwinner,sun5i-a13-ts";
			reg = <0x1c25000 0x100>;
			interrupts = <0x0 0x1d 0x4>;
			#thermal-sensor-cells = <0x0>;
			linux,phandle = <0x7>;
			phandle = <0x7>;
		};

		serial@01c28000 {
			compatible = "snps,dw-apb-uart";
			reg = <0x1c28000 0x400>;
			interrupts = <0x0 0x1 0x4>;
			reg-shift = <0x2>;
			reg-io-width = <0x4>;
			clocks = <0x36 0x10>;
			status = "okay";
			pinctrl-names = "default";
			pinctrl-0 = <0x37>;
		};

		serial@01c28400 {
			compatible = "snps,dw-apb-uart";
			reg = <0x1c28400 0x400>;
			interrupts = <0x0 0x2 0x4>;
			reg-shift = <0x2>;
			reg-io-width = <0x4>;
			clocks = <0x36 0x11>;
			status = "disabled";
		};

		serial@01c28800 {
			compatible = "snps,dw-apb-uart";
			reg = <0x1c28800 0x400>;
			interrupts = <0x0 0x3 0x4>;
			reg-shift = <0x2>;
			reg-io-width = <0x4>;
			clocks = <0x36 0x12>;
			status = "disabled";
		};

		serial@01c28c00 {
			compatible = "snps,dw-apb-uart";
			reg = <0x1c28c00 0x400>;
			interrupts = <0x0 0x4 0x4>;
			reg-shift = <0x2>;
			reg-io-width = <0x4>;
			clocks = <0x36 0x13>;
			status = "okay";
			pinctrl-names = "default";
			pinctrl-0 = <0x38>;
		};

		serial@01c29000 {
			compatible = "snps,dw-apb-uart";
			reg = <0x1c29000 0x400>;
			interrupts = <0x0 0x11 0x4>;
			reg-shift = <0x2>;
			reg-io-width = <0x4>;
			clocks = <0x36 0x14>;
			status = "disabled";
		};

		serial@01c29400 {
			compatible = "snps,dw-apb-uart";
			reg = <0x1c29400 0x400>;
			interrupts = <0x0 0x12 0x4>;
			reg-shift = <0x2>;
			reg-io-width = <0x4>;
			clocks = <0x36 0x15>;
			status = "disabled";
		};

		serial@01c29800 {
			compatible = "snps,dw-apb-uart";
			reg = <0x1c29800 0x400>;
			interrupts = <0x0 0x13 0x4>;
			reg-shift = <0x2>;
			reg-io-width = <0x4>;
			clocks = <0x36 0x16>;
			status = "disabled";
		};

		serial@01c29c00 {
			compatible = "snps,dw-apb-uart";
			reg = <0x1c29c00 0x400>;
			interrupts = <0x0 0x14 0x4>;
			reg-shift = <0x2>;
			reg-io-width = <0x4>;
			clocks = <0x36 0x17>;
			status = "okay";
			pinctrl-names = "default";
			pinctrl-0 = <0x39>;
		};

		i2c@01c2ac00 {
			compatible = "allwinner,sun7i-a20-i2c", "allwinner,sun4i-a10-i2c";
			reg = <0x1c2ac00 0x400>;
			interrupts = <0x0 0x7 0x4>;
			clocks = <0x36 0x0>;
			status = "okay";
			#address-cells = <0x1>;
			#size-cells = <0x0>;
			pinctrl-names = "default";
			pinctrl-0 = <0x3a>;

			pmic@34 {
				reg = <0x34>;
				interrupt-parent = <0x3b>;
				interrupts = <0x0 0x8>;
				compatible = "x-powers,axp209";
				interrupt-controller;
				#interrupt-cells = <0x1>;

				regulators {
					x-powers,dcdc-freq = <0x5dc>;

					dcdc2 {
						regulator-name = "vdd-cpu";
						regulator-always-on;
						regulator-min-microvolt = <0xf4240>;
						regulator-max-microvolt = <0x155cc0>;
						linux,phandle = <0x6>;
						phandle = <0x6>;
					};

					dcdc3 {
						regulator-name = "vdd-int-dll";
						regulator-always-on;
						regulator-min-microvolt = <0xf4240>;
						regulator-max-microvolt = <0x155cc0>;
					};

					ldo1 {
						regulator-always-on;
						regulator-min-microvolt = <0x13d620>;
						regulator-max-microvolt = <0x13d620>;
						regulator-name = "vdd-rtc";
					};

					ldo2 {
						regulator-name = "avcc";
						regulator-always-on;
						regulator-min-microvolt = <0x2dc6c0>;
						regulator-max-microvolt = <0x2dc6c0>;
					};

					ldo3 {
						regulator-name = "ldo3";
					};

					ldo4 {
						regulator-name = "ldo4";
					};

					ldo5 {
						regulator-name = "ldo5";
					};
				};

				usb_power_supply {
					compatible = "x-powers,axp202-usb-power-supply";
					status = "okay";
					linux,phandle = <0x2a>;
					phandle = <0x2a>;
				};
			};
		};

		i2c@01c2b000 {
			compatible = "allwinner,sun7i-a20-i2c", "allwinner,sun4i-a10-i2c";
			reg = <0x1c2b000 0x400>;
			interrupts = <0x0 0x8 0x4>;
			clocks = <0x36 0x1>;
			status = "disabled";
			#address-cells = <0x1>;
			#size-cells = <0x0>;
		};

		i2c@01c2b400 {
			compatible = "allwinner,sun7i-a20-i2c", "allwinner,sun4i-a10-i2c";
			reg = <0x1c2b400 0x400>;
			interrupts = <0x0 0x9 0x4>;
			clocks = <0x36 0x2>;
			status = "okay";
			#address-cells = <0x1>;
			#size-cells = <0x0>;
			pinctrl-names = "default";
			pinctrl-0 = <0x3c>;
		};

		i2c@01c2b800 {
			compatible = "allwinner,sun7i-a20-i2c", "allwinner,sun4i-a10-i2c";
			reg = <0x1c2b800 0x400>;
			interrupts = <0x0 0x58 0x4>;
			clocks = <0x36 0x3>;
			status = "disabled";
			#address-cells = <0x1>;
			#size-cells = <0x0>;
		};

		i2c@01c2c000 {
			compatible = "allwinner,sun7i-a20-i2c", "allwinner,sun4i-a10-i2c";
			reg = <0x1c2c000 0x400>;
			interrupts = <0x0 0x59 0x4>;
			clocks = <0x36 0xf>;
			status = "disabled";
			#address-cells = <0x1>;
			#size-cells = <0x0>;
		};

		ethernet@01c50000 {
			compatible = "allwinner,sun7i-a20-gmac";
			reg = <0x1c50000 0x10000>;
			interrupts = <0x0 0x55 0x4>;
			interrupt-names = "macirq";
			clocks = <0x3 0x31 0x3d>;
			clock-names = "stmmaceth", "allwinner_gmac_tx";
			snps,pbl = <0x2>;
			snps,fixed-burst;
			snps,force_sf_dma_mode;
			status = "okay";
			#address-cells = <0x1>;
			#size-cells = <0x0>;
			pinctrl-names = "default";
			pinctrl-0 = <0x3e>;
			phy = <0x3f>;
			phy-mode = "rgmii";
			phy-supply = <0x40>;

			ethernet-phy@1 {
				reg = <0x1>;
				linux,phandle = <0x3f>;
				phandle = <0x3f>;
			};
		};

		hstimer@01c60000 {
			compatible = "allwinner,sun7i-a20-hstimer";
			reg = <0x1c60000 0x1000>;
			interrupts = <0x0 0x51 0x4 0x0 0x52 0x4 0x0 0x53 0x4 0x0 0x54 0x4>;
			clocks = <0x3 0x1c>;
		};

		interrupt-controller@01c81000 {
			compatible = "arm,cortex-a7-gic", "arm,cortex-a15-gic";
			reg = <0x1c81000 0x1000 0x1c82000 0x1000 0x1c84000 0x2000 0x1c86000 0x2000>;
			interrupt-controller;
			#interrupt-cells = <0x3>;
			interrupts = <0x1 0x9 0xf04>;
			linux,phandle = <0x1>;
			phandle = <0x1>;
		};

		ps2@01c2a000 {
			compatible = "allwinner,sun4i-a10-ps2";
			reg = <0x1c2a000 0x400>;
			interrupts = <0x0 0x3e 0x4>;
			clocks = <0x36 0x6>;
			status = "disabled";
		};

		ps2@01c2a400 {
			compatible = "allwinner,sun4i-a10-ps2";
			reg = <0x1c2a400 0x400>;
			interrupts = <0x0 0x3f 0x4>;
			clocks = <0x36 0x7>;
			status = "disabled";
		};
	};

	ahci-5v {
		compatible = "regulator-fixed";
		pinctrl-names = "default";
		pinctrl-0 = <0x41>;
		regulator-name = "ahci-5v";
		regulator-min-microvolt = <0x4c4b40>;
		regulator-max-microvolt = <0x4c4b40>;
		regulator-boot-on;
		enable-active-high;
		gpio = <0x22 0x1 0x8 0x0>;
		status = "disabled";
	};

	usb0-vbus {
		compatible = "regulator-fixed";
		pinctrl-names = "default";
		pinctrl-0 = <0x42>;
		regulator-name = "usb0-vbus";
		regulator-min-microvolt = <0x4c4b40>;
		regulator-max-microvolt = <0x4c4b40>;
		enable-active-high;
		gpio = <0x22 0x1 0x9 0x0>;
		status = "okay";
		linux,phandle = <0x2b>;
		phandle = <0x2b>;
	};

	usb1-vbus {
		compatible = "regulator-fixed";
		pinctrl-names = "default";
		pinctrl-0 = <0x43>;
		regulator-name = "usb1-vbus";
		regulator-min-microvolt = <0x4c4b40>;
		regulator-max-microvolt = <0x4c4b40>;
		regulator-boot-on;
		enable-active-high;
		gpio = <0x22 0x7 0x6 0x0>;
		status = "okay";
		linux,phandle = <0x2c>;
		phandle = <0x2c>;
	};

	usb2-vbus {
		compatible = "regulator-fixed";
		pinctrl-names = "default";
		pinctrl-0 = <0x44>;
		regulator-name = "usb2-vbus";
		regulator-min-microvolt = <0x4c4b40>;
		regulator-max-microvolt = <0x4c4b40>;
		regulator-boot-on;
		enable-active-high;
		gpio = <0x22 0x7 0x3 0x0>;
		status = "okay";
		linux,phandle = <0x2d>;
		phandle = <0x2d>;
	};

	vcc3v0 {
		compatible = "regulator-fixed";
		regulator-name = "vcc3v0";
		regulator-min-microvolt = <0x2dc6c0>;
		regulator-max-microvolt = <0x2dc6c0>;
	};

	vcc3v3 {
		compatible = "regulator-fixed";
		regulator-name = "vcc3v3";
		regulator-min-microvolt = <0x325aa0>;
		regulator-max-microvolt = <0x325aa0>;
		linux,phandle = <0x21>;
		phandle = <0x21>;
	};

	vcc5v0 {
		compatible = "regulator-fixed";
		regulator-name = "vcc5v0";
		regulator-min-microvolt = <0x4c4b40>;
		regulator-max-microvolt = <0x4c4b40>;
	};

	leds {
		compatible = "gpio-leds";
		pinctrl-names = "default";
		pinctrl-0 = <0x45>;

		green {
			label = "bananapi:green:usr";
			gpios = <0x22 0x7 0x18 0x0>;
		};
	};

	gmac-3v3 {
		compatible = "regulator-fixed";
		pinctrl-names = "default";
		pinctrl-0 = <0x46>;
		regulator-name = "gmac-3v3";
		regulator-min-microvolt = <0x325aa0>;
		regulator-max-microvolt = <0x325aa0>;
		startup-delay-us = <0x186a0>;
		enable-active-high;
		gpio = <0x22 0x7 0x17 0x0>;
		linux,phandle = <0x40>;
		phandle = <0x40>;
	};
};
